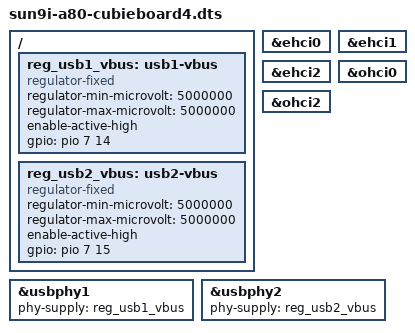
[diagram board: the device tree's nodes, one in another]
/* $NetBSD: sun9i-a80-cubieboard4.dts,v 1.1 2019/05/28 21:57:21 jmcneill Exp $ */

/*-
 * Copyright (c) 2019 Jared McNeill <jmcneill@invisible.ca>
 * All rights reserved.
 *
 * Redistribution and use in source and binary forms, with or without
 * modification, are permitted provided that the following conditions
 * are met:
 * 1. Redistributions of source code must retain the above copyright
 *    notice, this list of conditions and the following disclaimer.
 * 2. Redistributions in binary form must reproduce the above copyright
 *    notice, this list of conditions and the following disclaimer in the
 *    documentation and/or other materials provided with the distribution.
 *
 * THIS SOFTWARE IS PROVIDED BY THE AUTHOR ``AS IS'' AND ANY EXPRESS OR
 * IMPLIED WARRANTIES, INCLUDING, BUT NOT LIMITED TO, THE IMPLIED WARRANTIES
 * OF MERCHANTABILITY AND FITNESS FOR A PARTICULAR PURPOSE ARE DISCLAIMED.
 * IN NO EVENT SHALL THE AUTHOR BE LIABLE FOR ANY DIRECT, INDIRECT,
 * INCIDENTAL, SPECIAL, EXEMPLARY, OR CONSEQUENTIAL DAMAGES (INCLUDING,
 * BUT NOT LIMITED TO, PROCUREMENT OF SUBSTITUTE GOODS OR SERVICES;
 * LOSS OF USE, DATA, OR PROFITS; OR BUSINESS INTERRUPTION) HOWEVER CAUSED
 * AND ON ANY THEORY OF LIABILITY, WHETHER IN CONTRACT, STRICT LIABILITY,
 * OR TORT (INCLUDING NEGLIGENCE OR OTHERWISE) ARISING IN ANY WAY
 * OUT OF THE USE OF THIS SOFTWARE, EVEN IF ADVISED OF THE POSSIBILITY OF
 * SUCH DAMAGE.
 */

#include "../../../external/gpl2/dts/dist/arch/arm/boot/dts/sun9i-a80-cubieboard4.dts"

/ {
	reg_usb1_vbus: usb1-vbus {
		compatible = "regulator-fixed";
		pinctrl-names = "default";
		regulator-min-microvolt = <5000000>;
		regulator-max-microvolt = <5000000>;
		enable-active-high;
		gpio = <&pio 7 14 GPIO_ACTIVE_HIGH>;	/* PH14 */
	};

	reg_usb2_vbus: usb2-vbus {
		compatible = "regulator-fixed";
		pinctrl-names = "default";
		regulator-min-microvolt = <5000000>;
		regulator-max-microvolt = <5000000>;
		enable-active-high;
		gpio = <&pio 7 15 GPIO_ACTIVE_HIGH>;	/* PH15 */
	};
};

&ehci0 {
	status = "okay";
};

&ehci1 {
	status = "okay";
};

&ehci2 {
	status = "okay";
};

&ohci0 {
	status = "okay";
};

&ohci2 {
	status = "okay";
};

&usbphy1 {
	phy-supply = <&reg_usb1_vbus>;
	status = "okay";
};

&usbphy2 {
	phy-supply = <&reg_usb2_vbus>;
	status = "okay";
};
